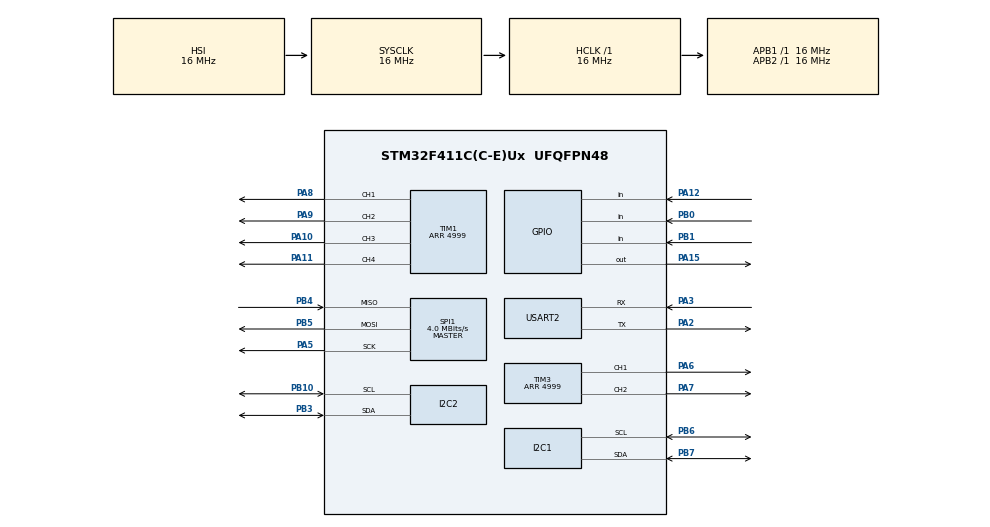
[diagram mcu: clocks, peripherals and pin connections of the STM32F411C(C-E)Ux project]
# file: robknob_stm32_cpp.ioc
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I2C1.I2C_Mode=I2C_Fast
I2C2.I2C_Mode=I2C_Fast
Mcu.Family=STM32F4
Mcu.Name=STM32F411C(C-E)Ux
Mcu.Package=UFQFPN48
NVIC.I2C1_ER_IRQn=true\:0\:0\:false\:false\:true\:true\:true\:true
NVIC.I2C1_EV_IRQn=true\:0\:0\:false\:false\:true\:true\:true\:true
NVIC.I2C2_ER_IRQn=true\:0\:0\:false\:false\:true\:true\:true\:true
NVIC.I2C2_EV_IRQn=true\:0\:0\:false\:false\:true\:true\:true\:true
NVIC.PriorityGroup=NVIC_PRIORITYGROUP_4
NVIC.USART2_IRQn=true\:0\:0\:false\:false\:true\:true\:true\:true
PA0-WKUP.Mode=SYS_WakeUp0
PA0-WKUP.Signal=SYS_WKUP
PA10.Signal=S_TIM1_CH3
PA11.Signal=S_TIM1_CH4
PA12.Signal=GPIO_Input
PA13.Mode=Serial_Wire
PA13.Signal=SYS_JTMS-SWDIO
PA14.Mode=Serial_Wire
PA14.Signal=SYS_JTCK-SWCLK
PA15.GPIO_PuPd=GPIO_PULLUP
PA15.Signal=GPIO_Output
PA2.Mode=Asynchronous
PA2.Signal=USART2_TX
PA3.Mode=Asynchronous
PA3.Signal=USART2_RX
PA5.Mode=Full_Duplex_Master
PA5.Signal=SPI1_SCK
PA6.Signal=S_TIM3_CH1
PA7.Signal=S_TIM3_CH2
PA8.Signal=S_TIM1_CH1
PA9.Signal=S_TIM1_CH2
PB0.Signal=GPIO_Input
PB1.Signal=GPIO_Input
PB10.Mode=I2C
PB10.Signal=I2C2_SCL
PB3.Mode=I2C
PB3.Signal=I2C2_SDA
PB4.Mode=Full_Duplex_Master
PB4.Signal=SPI1_MISO
PB5.Mode=Full_Duplex_Master
PB5.Signal=SPI1_MOSI
PB6.Mode=I2C
PB6.Signal=I2C1_SCL
PB7.Mode=I2C
PB7.Signal=I2C1_SDA
ProjectManager.HeapSize=0x200
ProjectManager.StackSize=0x400
ProjectManager.TargetToolchain=STM32CubeIDE
RCC.AHBFreq_Value=16000000
RCC.APB1Freq_Value=16000000
RCC.APB2Freq_Value=16000000
RCC.CortexFreq_Value=16000000
RCC.HSE_VALUE=25000000
RCC.HSI_VALUE=16000000
RCC.LSE_VALUE=32768
RCC.SYSCLKFreq_VALUE=16000000
RCC.VCOOutputFreq_Value=192000000
SH.S_TIM1_CH1.0=TIM1_CH1,PWM Generation1 CH1
SH.S_TIM1_CH2.0=TIM1_CH2,PWM Generation2 CH2
SH.S_TIM1_CH3.0=TIM1_CH3,PWM Generation3 CH3
SH.S_TIM1_CH4.0=TIM1_CH4,PWM Generation4 CH4
SH.S_TIM3_CH1.0=TIM3_CH1,PWM Generation1 CH1
SH.S_TIM3_CH2.0=TIM3_CH2,PWM Generation2 CH2
SPI1.BaudRatePrescaler=SPI_BAUDRATEPRESCALER_4
SPI1.CLKPolarity=SPI_POLARITY_HIGH
SPI1.CalculateBaudRate=4.0 MBits/s
SPI1.DataSize=SPI_DATASIZE_16BIT
SPI1.Direction=SPI_DIRECTION_2LINES
SPI1.Mode=SPI_MODE_MASTER
SPI1.VirtualType=VM_MASTER
TIM1.Channel-PWM\ Generation1\ CH1=TIM_CHANNEL_1
TIM1.Channel-PWM\ Generation2\ CH2=TIM_CHANNEL_2
TIM1.Channel-PWM\ Generation3\ CH3=TIM_CHANNEL_3
TIM1.Channel-PWM\ Generation4\ CH4=TIM_CHANNEL_4
TIM1.Period=4999
TIM2.Prescaler=99
TIM3.Channel-PWM\ Generation1\ CH1=TIM_CHANNEL_1
TIM3.Channel-PWM\ Generation2\ CH2=TIM_CHANNEL_2
TIM3.Period=4999
USART2.VirtualMode=VM_ASYNC
VP_TIM1_VS_ClockSourceINT.Mode=Internal
VP_TIM2_VS_ClockSourceINT.Mode=Internal
VP_TIM3_VS_ClockSourceINT.Mode=Internal
board=custom

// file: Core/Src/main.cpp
/* USER CODE BEGIN Header */
/**
  ******************************************************************************
  * @file           : main.c
  * @brief          : Main program body
  ******************************************************************************
  * @attention
  *
  * Copyright (c) 2024 STMicroelectronics.
  * All rights reserved.
  *
  * This software is licensed under terms that can be found in the LICENSE file
  * in the root directory of this software component.
  * If no LICENSE file comes with this software, it is provided AS-IS.
  *
  ******************************************************************************
  */
/* USER CODE END Header */
#include "main.h"
#include "SimpleFOC_stm32.h"

I2C_HandleTypeDef hi2c1;
I2C_HandleTypeDef hi2c2;

SPI_HandleTypeDef hspi1;

TIM_HandleTypeDef htim1;
TIM_HandleTypeDef htim2;
TIM_HandleTypeDef htim3;

UART_HandleTypeDef huart2;

/* USER CODE BEGIN PV */
uint8_t acc[6];
uint8_t gyro[6];
/* USER CODE END PV */

void SystemClock_Config(void);
static void MX_GPIO_Init(void);
static void MX_I2C1_Init(void);
static void MX_I2C2_Init(void);
static void MX_SPI1_Init(void);
static void MX_TIM1_Init(void);
static void MX_TIM2_Init(void);
static void MX_TIM3_Init(void);
static void MX_USART2_UART_Init(void);

int main(void)
{

  /* MCU Configuration--------------------------------------------------------*/

  /* Reset of all peripherals, Initializes the Flash interface and the Systick. */
  HAL_Init();

  /* Configure the system clock */
  SystemClock_Config();

  /* Initialize all configured peripherals */
  MX_GPIO_Init();
  MX_I2C1_Init();
  MX_I2C2_Init();
  MX_SPI1_Init();
  MX_TIM1_Init();
  MX_TIM2_Init();
  MX_TIM3_Init();
  MX_USART2_UART_Init();

  /* Infinite loop */
  while (1)
  {

  }
}

void SystemClock_Config(void)
{
  RCC_OscInitTypeDef RCC_OscInitStruct = {0};
  RCC_ClkInitTypeDef RCC_ClkInitStruct = {0};

  /** Configure the main internal regulator output voltage
  */
  __HAL_RCC_PWR_CLK_ENABLE();
  __HAL_PWR_VOLTAGESCALING_CONFIG(PWR_REGULATOR_VOLTAGE_SCALE1);

  /** Initializes the RCC Oscillators according to the specified parameters
  * in the RCC_OscInitTypeDef structure.
  */
  RCC_OscInitStruct.OscillatorType = RCC_OSCILLATORTYPE_HSI;
  RCC_OscInitStruct.HSIState = RCC_HSI_ON;
  RCC_OscInitStruct.HSICalibrationValue = RCC_HSICALIBRATION_DEFAULT;
  RCC_OscInitStruct.PLL.PLLState = RCC_PLL_NONE;
  if (HAL_RCC_OscConfig(&RCC_OscInitStruct) != HAL_OK)
  {
    Error_Handler();
  }

  /** Initializes the CPU, AHB and APB buses clocks
  */
  RCC_ClkInitStruct.ClockType = RCC_CLOCKTYPE_HCLK|RCC_CLOCKTYPE_SYSCLK
                              |RCC_CLOCKTYPE_PCLK1|RCC_CLOCKTYPE_PCLK2;
  RCC_ClkInitStruct.SYSCLKSource = RCC_SYSCLKSOURCE_HSI;
  RCC_ClkInitStruct.AHBCLKDivider = RCC_SYSCLK_DIV1;
  RCC_ClkInitStruct.APB1CLKDivider = RCC_HCLK_DIV1;
  RCC_ClkInitStruct.APB2CLKDivider = RCC_HCLK_DIV1;

  if (HAL_RCC_ClockConfig(&RCC_ClkInitStruct, FLASH_LATENCY_0) != HAL_OK)
  {
    Error_Handler();
  }
}

static void MX_I2C1_Init(void)
{

  hi2c1.Instance = I2C1;
  hi2c1.Init.ClockSpeed = 400000;
  hi2c1.Init.DutyCycle = I2C_DUTYCYCLE_2;
  hi2c1.Init.OwnAddress1 = 0;
  hi2c1.Init.AddressingMode = I2C_ADDRESSINGMODE_7BIT;
  hi2c1.Init.DualAddressMode = I2C_DUALADDRESS_DISABLE;
  hi2c1.Init.OwnAddress2 = 0;
  hi2c1.Init.GeneralCallMode = I2C_GENERALCALL_DISABLE;
  hi2c1.Init.NoStretchMode = I2C_NOSTRETCH_DISABLE;
  if (HAL_I2C_Init(&hi2c1) != HAL_OK)
  {
    Error_Handler();
  }

}

static void MX_I2C2_Init(void)
{

  hi2c2.Instance = I2C2;
  hi2c2.Init.ClockSpeed = 400000;
  hi2c2.Init.DutyCycle = I2C_DUTYCYCLE_2;
  hi2c2.Init.OwnAddress1 = 0;
  hi2c2.Init.AddressingMode = I2C_ADDRESSINGMODE_7BIT;
  hi2c2.Init.DualAddressMode = I2C_DUALADDRESS_DISABLE;
  hi2c2.Init.OwnAddress2 = 0;
  hi2c2.Init.GeneralCallMode = I2C_GENERALCALL_DISABLE;
  hi2c2.Init.NoStretchMode = I2C_NOSTRETCH_DISABLE;
  if (HAL_I2C_Init(&hi2c2) != HAL_OK)
  {
    Error_Handler();
  }

}

static void MX_SPI1_Init(void)
{

  /* SPI1 parameter configuration*/
  hspi1.Instance = SPI1;
  hspi1.Init.Mode = SPI_MODE_MASTER;
  hspi1.Init.Direction = SPI_DIRECTION_2LINES;
  hspi1.Init.DataSize = SPI_DATASIZE_16BIT;
  hspi1.Init.CLKPolarity = SPI_POLARITY_HIGH;
  hspi1.Init.CLKPhase = SPI_PHASE_1EDGE;
  hspi1.Init.NSS = SPI_NSS_SOFT;
  hspi1.Init.BaudRatePrescaler = SPI_BAUDRATEPRESCALER_4;
  hspi1.Init.FirstBit = SPI_FIRSTBIT_MSB;
  hspi1.Init.TIMode = SPI_TIMODE_DISABLE;
  hspi1.Init.CRCCalculation = SPI_CRCCALCULATION_DISABLE;
  hspi1.Init.CRCPolynomial = 10;
  if (HAL_SPI_Init(&hspi1) != HAL_OK)
  {
    Error_Handler();
  }

}

static void MX_TIM1_Init(void)
{

  TIM_ClockConfigTypeDef sClockSourceConfig = {0};
  TIM_MasterConfigTypeDef sMasterConfig = {0};
  TIM_OC_InitTypeDef sConfigOC = {0};
  TIM_BreakDeadTimeConfigTypeDef sBreakDeadTimeConfig = {0};

  htim1.Instance = TIM1;
  htim1.Init.Prescaler = 0;
  htim1.Init.CounterMode = TIM_COUNTERMODE_UP;
  htim1.Init.Period = 4999;
  htim1.Init.ClockDivision = TIM_CLOCKDIVISION_DIV1;
  htim1.Init.RepetitionCounter = 0;
  htim1.Init.AutoReloadPreload = TIM_AUTORELOAD_PRELOAD_DISABLE;
  if (HAL_TIM_Base_Init(&htim1) != HAL_OK)
  {
    Error_Handler();
  }
  sClockSourceConfig.ClockSource = TIM_CLOCKSOURCE_INTERNAL;
  if (HAL_TIM_ConfigClockSource(&htim1, &sClockSourceConfig) != HAL_OK)
  {
    Error_Handler();
  }
  if (HAL_TIM_PWM_Init(&htim1) != HAL_OK)
  {
    Error_Handler();
  }
  sMasterConfig.MasterOutputTrigger = TIM_TRGO_RESET;
  sMasterConfig.MasterSlaveMode = TIM_MASTERSLAVEMODE_DISABLE;
  if (HAL_TIMEx_MasterConfigSynchronization(&htim1, &sMasterConfig) != HAL_OK)
  {
    Error_Handler();
  }
  sConfigOC.OCMode = TIM_OCMODE_PWM1;
  sConfigOC.Pulse = 0;
  sConfigOC.OCPolarity = TIM_OCPOLARITY_HIGH;
  sConfigOC.OCNPolarity = TIM_OCNPOLARITY_HIGH;
  sConfigOC.OCFastMode = TIM_OCFAST_DISABLE;
  sConfigOC.OCIdleState = TIM_OCIDLESTATE_RESET;
  sConfigOC.OCNIdleState = TIM_OCNIDLESTATE_RESET;
  if (HAL_TIM_PWM_ConfigChannel(&htim1, &sConfigOC, TIM_CHANNEL_1) != HAL_OK)
  {
    Error_Handler();
  }
  if (HAL_TIM_PWM_ConfigChannel(&htim1, &sConfigOC, TIM_CHANNEL_2) != HAL_OK)
  {
    Error_Handler();
  }
  if (HAL_TIM_PWM_ConfigChannel(&htim1, &sConfigOC, TIM_CHANNEL_3) != HAL_OK)
  {
    Error_Handler();
  }
  if (HAL_TIM_PWM_ConfigChannel(&htim1, &sConfigOC, TIM_CHANNEL_4) != HAL_OK)
  {
    Error_Handler();
  }
  sBreakDeadTimeConfig.OffStateRunMode = TIM_OSSR_DISABLE;
  sBreakDeadTimeConfig.OffStateIDLEMode = TIM_OSSI_DISABLE;
  sBreakDeadTimeConfig.LockLevel = TIM_LOCKLEVEL_OFF;
  sBreakDeadTimeConfig.DeadTime = 0;
  sBreakDeadTimeConfig.BreakState = TIM_BREAK_DISABLE;
  sBreakDeadTimeConfig.BreakPolarity = TIM_BREAKPOLARITY_HIGH;
  sBreakDeadTimeConfig.AutomaticOutput = TIM_AUTOMATICOUTPUT_DISABLE;
  if (HAL_TIMEx_ConfigBreakDeadTime(&htim1, &sBreakDeadTimeConfig) != HAL_OK)
  {
    Error_Handler();
  }
  HAL_TIM_MspPostInit(&htim1);

}

static void MX_TIM2_Init(void)
{

  TIM_ClockConfigTypeDef sClockSourceConfig = {0};
  TIM_MasterConfigTypeDef sMasterConfig = {0};

  htim2.Instance = TIM2;
  htim2.Init.Prescaler = 99;
  htim2.Init.CounterMode = TIM_COUNTERMODE_UP;
  htim2.Init.Period = 4294967295;
  htim2.Init.ClockDivision = TIM_CLOCKDIVISION_DIV1;
  htim2.Init.AutoReloadPreload = TIM_AUTORELOAD_PRELOAD_DISABLE;
  if (HAL_TIM_Base_Init(&htim2) != HAL_OK)
  {
    Error_Handler();
  }
  sClockSourceConfig.ClockSource = TIM_CLOCKSOURCE_INTERNAL;
  if (HAL_TIM_ConfigClockSource(&htim2, &sClockSourceConfig) != HAL_OK)
  {
    Error_Handler();
  }
  sMasterConfig.MasterOutputTrigger = TIM_TRGO_RESET;
  sMasterConfig.MasterSlaveMode = TIM_MASTERSLAVEMODE_DISABLE;
  if (HAL_TIMEx_MasterConfigSynchronization(&htim2, &sMasterConfig) != HAL_OK)
  {
    Error_Handler();
  }

}

static void MX_TIM3_Init(void)
{

  TIM_ClockConfigTypeDef sClockSourceConfig = {0};
  TIM_MasterConfigTypeDef sMasterConfig = {0};
  TIM_OC_InitTypeDef sConfigOC = {0};

  htim3.Instance = TIM3;
  htim3.Init.Prescaler = 0;
  htim3.Init.CounterMode = TIM_COUNTERMODE_UP;
  htim3.Init.Period = 4999;
  htim3.Init.ClockDivision = TIM_CLOCKDIVISION_DIV1;
  htim3.Init.AutoReloadPreload = TIM_AUTORELOAD_PRELOAD_DISABLE;
  if (HAL_TIM_Base_Init(&htim3) != HAL_OK)
  {
    Error_Handler();
  }
  sClockSourceConfig.ClockSource = TIM_CLOCKSOURCE_INTERNAL;
  if (HAL_TIM_ConfigClockSource(&htim3, &sClockSourceConfig) != HAL_OK)
  {
    Error_Handler();
  }
  if (HAL_TIM_PWM_Init(&htim3) != HAL_OK)
  {
    Error_Handler();
  }
  sMasterConfig.MasterOutputTrigger = TIM_TRGO_RESET;
  sMasterConfig.MasterSlaveMode = TIM_MASTERSLAVEMODE_DISABLE;
  if (HAL_TIMEx_MasterConfigSynchronization(&htim3, &sMasterConfig) != HAL_OK)
  {
    Error_Handler();
  }
  sConfigOC.OCMode = TIM_OCMODE_PWM1;
  sConfigOC.Pulse = 0;
  sConfigOC.OCPolarity = TIM_OCPOLARITY_HIGH;
  sConfigOC.OCFastMode = TIM_OCFAST_DISABLE;
  if (HAL_TIM_PWM_ConfigChannel(&htim3, &sConfigOC, TIM_CHANNEL_1) != HAL_OK)
  {
    Error_Handler();
  }
  if (HAL_TIM_PWM_ConfigChannel(&htim3, &sConfigOC, TIM_CHANNEL_2) != HAL_OK)
  {
    Error_Handler();
  }
  HAL_TIM_MspPostInit(&htim3);

}

static void MX_USART2_UART_Init(void)
{

  huart2.Instance = USART2;
  huart2.Init.BaudRate = 115200;
  huart2.Init.WordLength = UART_WORDLENGTH_8B;
  huart2.Init.StopBits = UART_STOPBITS_1;
  huart2.Init.Parity = UART_PARITY_NONE;
  huart2.Init.Mode = UART_MODE_TX_RX;
  huart2.Init.HwFlowCtl = UART_HWCONTROL_NONE;
  huart2.Init.OverSampling = UART_OVERSAMPLING_16;
  if (HAL_UART_Init(&huart2) != HAL_OK)
  {
    Error_Handler();
  }

}

static void MX_GPIO_Init(void)
{
  GPIO_InitTypeDef GPIO_InitStruct = {0};

  /* GPIO Ports Clock Enable */
  __HAL_RCC_GPIOA_CLK_ENABLE();
  __HAL_RCC_GPIOB_CLK_ENABLE();

  /*Configure GPIO pin Output Level */
  HAL_GPIO_WritePin(GPIOA, GPIO_PIN_15, GPIO_PIN_RESET);

  /*Configure GPIO pins : PB0 PB1 */
  GPIO_InitStruct.Pin = GPIO_PIN_0|GPIO_PIN_1;
  GPIO_InitStruct.Mode = GPIO_MODE_INPUT;
  GPIO_InitStruct.Pull = GPIO_NOPULL;
  HAL_GPIO_Init(GPIOB, &GPIO_InitStruct);

  /*Configure GPIO pin : PA12 */
  GPIO_InitStruct.Pin = GPIO_PIN_12;
  GPIO_InitStruct.Mode = GPIO_MODE_INPUT;
  GPIO_InitStruct.Pull = GPIO_NOPULL;
  HAL_GPIO_Init(GPIOA, &GPIO_InitStruct);

  /*Configure GPIO pin : PA15 */
  GPIO_InitStruct.Pin = GPIO_PIN_15;
  GPIO_InitStruct.Mode = GPIO_MODE_OUTPUT_PP;
  GPIO_InitStruct.Pull = GPIO_PULLUP;
  GPIO_InitStruct.Speed = GPIO_SPEED_FREQ_LOW;
  HAL_GPIO_Init(GPIOA, &GPIO_InitStruct);

}

/* USER CODE BEGIN 4 */
void acc_write(uint8_t* cmd){
	HAL_I2C_Master_Transmit(&hi2c1, 0x18 << 1, cmd, sizeof(cmd),HAL_MAX_DELAY);
}

void acc_read(){
	uint8_t acc[6];
	HAL_I2C_Master_Receive(&hi2c1, 0x18 << 1, acc, 6, 1000);
}

void gyro_write(uint8_t* cmd){
	HAL_I2C_Master_Transmit(&hi2c1, 0x68 << 1, cmd, sizeof(cmd),HAL_MAX_DELAY);
}

void gyro_read(){
	uint8_t gyro[6];
	HAL_I2C_Master_Receive(&hi2c1, 0x68 << 1, gyro, 6, 1000);
}
/* USER CODE END 4 */

void Error_Handler(void)
{
  __disable_irq();
  while (1)
  {
  }
}
